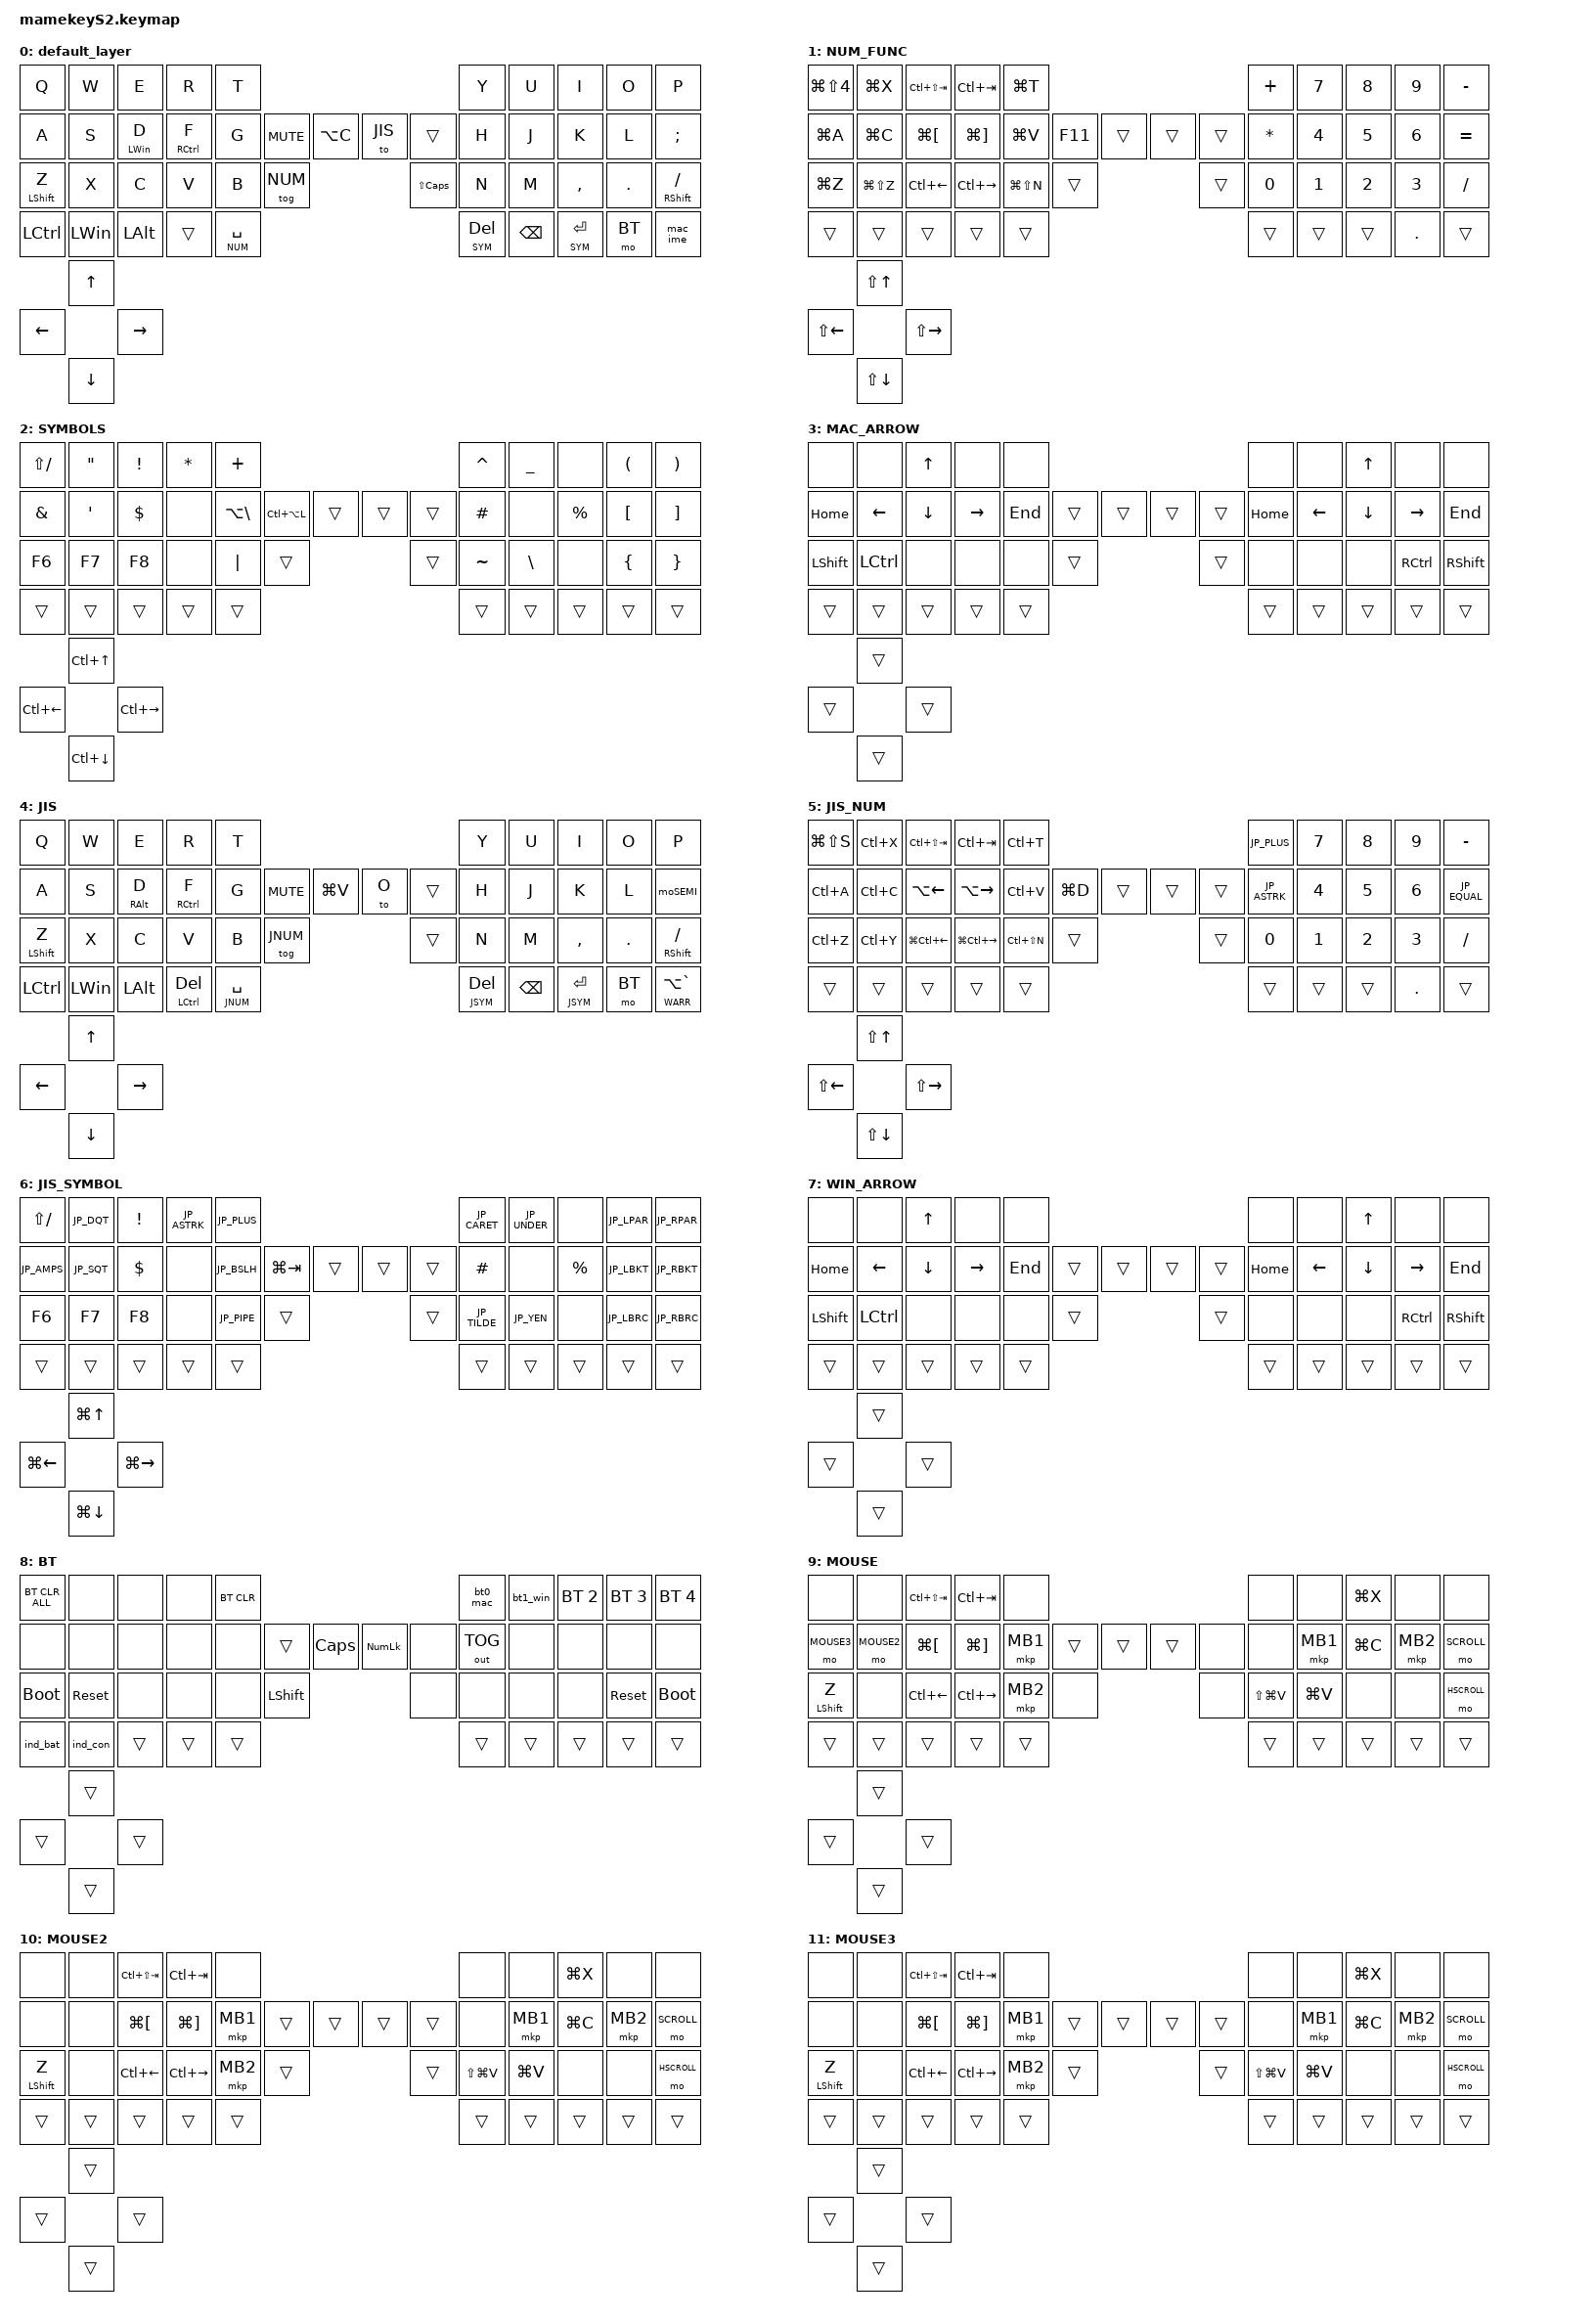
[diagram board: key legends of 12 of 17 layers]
#include <input/processors.dtsi>
#include <behaviors.dtsi>
#include <dt-bindings/zmk/keys.h>
#include <dt-bindings/zmk/bt.h>
#include <dt-bindings/zmk/outputs.h>
#include <dt-bindings/zmk/pointing.h>
#include <dt-bindings/zmk/input_transform.h>
#include <zephyr/dt-bindings/input/input-event-codes.h>


#include <behaviors/rgbled_widget.dtsi>

#define ZMK_POINTING_DEFAULT_SCRL_VAL 100

#define NUM 1 //MAC US
#define SYM 2 //MAC US
#define MARR 3 //MAC
#define JIS 4 //WIN JIS
#define JNUM 5 //WIN JIS
#define JSYM 6 //WIN JIS
#define WARR 7 //WIN
#define BT 8
#define MOUSE 9 //mac
#define MOUSE2 10 //mac lowspeed
#define MOUSE3 11 //mac highspeed
#define WMOUSE 12 //win
#define WMOUSE2 13 //win lowspeed
#define WMOUSE3 14 //win highspeed
#define SCROLL 15
#define HSCROLL 16 //high speed scroll


#define JP_ZKHK  GRAVE        // Zenkaku ↔ Hankaku ↔ Kanji (半角 ↔ 全角 ↔ 漢字)
#define JP_MINUS MINUS        // -
#define JP_CARET EQUAL        // ^
#define JP_YEN   INT3         // ¥
#define JP_AT    LBKT         // @
#define JP_LBKT  RBKT         // [
#define JP_EISU  CAPS         // Eisū (英数)
#define JP_SEMI  SEMI         // ;
#define JP_COLON SQT          // :
#define JP_RBKT  NUHS         // ]
#define JP_COMMA COMMA        // ,
#define JP_DOT   DOT          // .
#define JP_SLASH SLASH        // /
#define JP_BSLH  INT1         // (backslash)
#define JP_MHEN  INT5         // Muhenkan (無変換)
#define JP_HENK  INT4         // Henkan (変換)
#define JP_KANA  INT2         // Katakana ↔ Hiragana ↔ Rōmaji (カタカナ ↔ ひらがな ↔ ローマ字)
#define JP_EXCL  LS(N1)       // !
#define JP_DQT   LS(N2)       // "
#define JP_HASH  LS(N3)       // #
#define JP_DLLR  LS(N4)       // $
#define JP_PRCNT LS(N5)       // %
#define JP_AMPS  LS(N6)       // &
#define JP_SQT   LS(N7)       // '
#define JP_LPAR  LS(N8)       // (
#define JP_RPAR  LS(N9)       // )
#define JP_EQUAL LS(JP_MINUS) // =
#define JP_TILDE LS(JP_CARET) // ~
#define JP_PIPE  LS(JP_YEN)   // |
#define JP_GRAVE LS(JP_AT)    // `
#define JP_LBRC  LS(JP_LBKT)  // {
#define JP_CAPS  LS(JP_EISU)  // Caps Lock
#define JP_PLUS  LS(JP_SEMI)  // +
#define JP_ASTRK LS(JP_COLON) // *
#define JP_RBRC  LS(JP_RBKT)  // }
#define JP_LT    LS(JP_COMMA) // <
#define JP_RT    LS(JP_DOT)   // >
#define JP_QMARK LS(JP_SLASH) // ?
#define JP_UNDER LS(JP_BSLH)  // _

    &mt {
        flavor = "balanced";
        quick-tap-ms = <0>;
    };


//Extend the Auto Mouse Layer (AML) timeout when a mouse key is pressed.
&mkp_input_listener {
         win_aml {
        layers = <4>;
        input-processors = <&zip_temp_layer 12 500>;
    };
         mac_aml {
        layers = <0>;
        input-processors = <&zip_temp_layer 9 500>;
    };
};

/ {

    macros {
        to_layer_0: to_layer_0 {
            compatible = "zmk,behavior-macro-one-param";
            #binding-cells = <1>;
            bindings = <&to 0 &macro_param_1to1 &kp MACRO_PLACEHOLDER>;
            label = "TO_LAYER_0";
        };
        
        exit_AML: exit_AML {
            compatible = "zmk,behavior-macro";
            wait-ms = <0>;
            tap-ms = <0>;
            #binding-cells = <0>;
            bindings = <&tog_off MOUSE>;
            label = "exit_AML";
        };
        
        kp_exit_AML: kp_exit_AML {
            compatible = "zmk,behavior-macro-one-param";
            wait-ms = <0>;
            tap-ms = <0>;
            #binding-cells = <1>;
            bindings = <&macro_param_1to1 &kp MACRO_PLACEHOLDER &exit_AML>;
            label = "KP_exit_AML";
        };

        bt0_mac: bt0_mac {
         compatible = "zmk,behavior-macro";
         #binding-cells = <0>;
         bindings = <&bt BT_SEL 0>, <&to 0>;
};

        bt1_win: bt1_win {
         compatible = "zmk,behavior-macro";
          #binding-cells = <0>;
          bindings = <&bt BT_SEL 1>, <&to JIS>;
};

        mac_ime: mac_ime_toggle {
            compatible = "zmk,behavior-macro";
            #binding-cells = <0>;
            bindings = 
                 <&macro_press>,
                 <&kp LCTRL>,
                 <&macro_tap>,
                 <&kp SPACE>,
                 <&macro_release>,
                 <&kp LCTRL>;
        };

    };
    
    combos {
        compatible = "zmk,combos";

        esc {
            bindings = <&kp ESC>;
            key-positions = <0 1>;
        };        

        shift_tab {
            bindings = <&kp LS(TAB)>;
            key-positions = <1 2>;
        };
        
         tab {
            bindings = <&kp TAB>;
            key-positions = <2 3>;
        };
        
        single_quotation {
            bindings = <&kp SINGLE_QUOTE>;
            layers = <0>; 
            key-positions = <5 6>;
        };
        
        single_quotation_JIS {
            bindings = <&kp JP_SQT>;
            layers = <JIS>; 
            key-positions = <5 6>;
        };
        
        double_quotation {
            bindings = <&kp DOUBLE_QUOTES>;
            layers = <0>; 
            key-positions = <3 4>;
        };
        
        double_quotation_JIS {
            bindings = <&kp JP_DQT>;
            layers = <JIS>; 
            key-positions = <3 4>;
        };
        
        
        minus {
            bindings = <&kp MINUS>;
            key-positions = <8 9>;
        };

        eq {
            bindings = <&kp EQUAL>;
            layers = <0>; 
            key-positions = <34 35>;
        };
        
        eq_JIS {
            bindings = <&kp JP_EQUAL>;
            layers = <JIS>; 
            key-positions = <34 35>;
        };

        mac_layer_L_PARENTHESIS {
            bindings = <&kp LEFT_PARENTHESIS>;
            layers = <0>;
            key-positions = <6 7>;
        };

        mac_layer_R_PARENTHESIS {
            bindings = <&kp RIGHT_PARENTHESIS>;
            layers = <0>;
            key-positions = <7 8>;
        };
        
        win_layer_L_PARENTHESIS {
            bindings = <&kp JP_LPAR>;
            layers = <JIS>;
            key-positions = <6 7>;
        };

        win_layer_R_PARENTHESIS {
            bindings = <&kp JP_RPAR>;
            layers = <JIS>;
            key-positions = <7 8>;
        };
        
        mac_layer_L_BRACKET {
            bindings = <&kp LEFT_BRACKET>;
            layers = <0>;
            key-positions = <20 21>;
        };

        mac_layer_R_BRACKET {
            bindings = <&kp RIGHT_BRACKET>;
            layers = <0>;
            key-positions = <21 22>;
        };
        
        win_layer_L_BRACKET {
            bindings = <&kp JP_LBKT>;
            layers = <JIS>;
            key-positions = <20 21>;
        };

        win_layer_R_BRACKET {
            bindings = <&kp JP_RBKT>;
            layers = <JIS>;
            key-positions = <21 22>;
        };
        
        enter {
            bindings = <&kp ENTER>;
            key-positions = <22 23>;
        };
        
        mac_layer_L_BRACE {
            bindings = <&kp LEFT_BRACE>;
            layers = <0>;
            key-positions = <32 33>;
        };

        mac_layer_R_BRACE {
            bindings = <&kp RIGHT_BRACE>;
            layers = <0>;
            key-positions = <33 34>;
        };
        
        win_layer_L_BRACE {
            bindings = <&kp JP_LBRC>;
            layers = <JIS>;
            key-positions = <32 33>;
        };

        win_layer_R_BRACE {
            bindings = <&kp JP_RBRC>;
            layers = <JIS>;
            key-positions = <33 34>;
        };
        
        mac_layer_arrow {
            bindings = <&mo MARR>;
            layers = <0>; 
            key-positions = <12 13>;
        };

        win_layer_arrow {
            bindings = <&mo WARR>;
            layers = <JIS>; 
            key-positions = <12 13>;
        };        

        ctrl_alt_del {
            bindings = <&kp LC(RA(DEL))>;
            key-positions = <24 25>;
        };

        atmark {
            bindings = <&kp AT_SIGN>; 
            layers = <0>;  
            key-positions = <10 11>;
        };
        atmark_JIS {
            bindings = <&kp JP_AT>; 
            layers = <JIS>;  
            key-positions = <10 11>;
        };
    };

  behaviors {
      
    lt_to_layer_0: lt_to_layer_0 {
            compatible = "zmk,behavior-hold-tap";
            label = "LAYER_TAP_TO_0";
            bindings = <&mo>, <&to_layer_0>;

            #binding-cells = <2>;
            tapping-term-ms = <200>;
        };
        
    tog_off: toggle_layer_off {
            compatible = "zmk,behavior-toggle-layer";
            #binding-cells = <1>;
            display-name = "Toggle Layer Off";
            toggle-mode = "off";
        };

    mt_exit_AML_on_tap: mt_exit_AML_on_tap {
            compatible = "zmk,behavior-hold-tap";
            label = "MT_exit_AML_ON_TAP";
            bindings = <&kp>, <&kp_exit_AML>;

            #binding-cells = <2>;
            tapping-term-ms = <200>;
            flavor = "balanced";
            quick-tap-ms = <200>;
        };    
        
    vol_up_down: behavior_sensor_rotate_volue_up_down {
            compatible = "zmk,behavior-sensor-rotate";
            #sensor-binding-cells = <0>;
            bindings = <&kp C_VOL_DN>, <&kp C_VOL_UP>;
        };         
    
    scroll_up_down: behavior_sensor_rotate_mouse_wheel_up_down {
            compatible = "zmk,behavior-sensor-rotate";
            #sensor-binding-cells = <0>;
            bindings = <&msc SCRL_UP>, <&msc SCRL_DOWN>;
            // 追加: スクロールのタップ時間を設定 (20ms)
            tap-ms = <20>;
        }; 
        
    scroll_left_right: behavior_sensor_rotate_mouse_wheel_left_right {
            compatible = "zmk,behavior-sensor-rotate";
            #sensor-binding-cells = <0>;
            bindings = <&msc SCRL_RIGHT>, <&msc SCRL_LEFT>;
            // 追加: スクロールのタップ時間を設定 (20ms)
            tap-ms = <20>;
        };   
        
    zoom_in_out_win: behavior_sensor_rotate_zoom_in_out_win {
            compatible = "zmk,behavior-sensor-rotate";
            #sensor-binding-cells = <0>;
            bindings = <&kp LC(JP_PLUS)>, <&kp LC(MINUS)>;
            // 追加: スクロールのタップ時間を設定 (20ms)
            tap-ms = <20>;
        };  
    zoom_in_out_mac: behavior_sensor_rotate_zoom_in_out_mac {
            compatible = "zmk,behavior-sensor-rotate";
            #sensor-binding-cells = <0>;
            bindings = <&kp LG(PLUS)>, <&kp LG(MINUS)>;
            // 追加: スクロールのタップ時間を設定 (20ms)
            tap-ms = <20>;
        };     
        
    td_mt: tap_dance_mod_tap {
            compatible = "zmk,behavior-tap-dance";
            #binding-cells = <0>;
            tapping-term-ms = <200>;
            bindings = <&lt WARR LA(GRAVE)>, <&kp LC(SPC)>; 
        };
        
//encorder control WIN  
  //positive
  
    //window change (alt D)   
    w_alt_p: win-alt-gui-positive {
        compatible = "zmk,behavior-mod-morph";
        #binding-cells = <0>;
        bindings = <&none>, <&kp TAB>;
        mods = <(MOD_LALT|MOD_RALT)>;
        keep-mods = <(MOD_RALT)>;
    };
    // tab move (Rctrl F)
    w_r_ctrl_p: win-right-ctrl-positive {
        compatible = "zmk,behavior-mod-morph";
        #binding-cells = <0>;
        bindings = <&none>, <&kp TAB>;
        mods = <(MOD_RCTL)>;
        keep-mods = <(MOD_RCTL)>;
    }; 
    // updown arrow (Lctrl)   
    w_ctrl_p: win-ctrl-positive {
        compatible = "zmk,behavior-mod-morph";
        #binding-cells = <0>;
        bindings = <&w_r_ctrl_p>, <&kp DOWN>;
        mods = <(MOD_LCTL)>;
    };
    // leftright arrow (shift)
    w_shift_p: win-shift-positive {
        compatible = "zmk,behavior-mod-morph";
        #binding-cells = <0>;
        bindings = <&none>, <&kp RIGHT>;
        mods = <(MOD_RSFT|MOD_LSFT)>;
    };     
    w_shift_ctrl_p: win-shift-ctrl-positive {
        compatible = "zmk,behavior-mod-morph";
        #binding-cells = <0>;
        bindings = <&w_shift_p>, <&w_ctrl_p>;
        mods = <(MOD_LCTL|MOD_RCTL)>;
    };
    //none is scroll down
    w_shift_ctrl_none_p: win_shift-ctrl-none-positive {
        compatible = "zmk,behavior-mod-morph";
        #binding-cells = <0>;
        bindings = <&msc SCRL_DOWN>, <&w_shift_ctrl_p>;
        mods = <(MOD_LSFT|MOD_LCTL|MOD_RSFT|MOD_RCTL)>;
    };
    win_enc_p: win-enc-positive {
        compatible = "zmk,behavior-mod-morph";
        #binding-cells = <0>;
        bindings = <&w_shift_ctrl_none_p>, <&w_alt_p>;
        mods = <(MOD_LALT|MOD_RALT)>;
    };
 
 //negative
   
    //window change (alt D)     
    w_alt_n: win-alt-gui-negative {
        compatible = "zmk,behavior-mod-morph";
        #binding-cells = <0>;
        bindings = <&none>, <&kp LS(TAB)>;
        mods = <(MOD_LALT|MOD_RALT)>;
        keep-mods = <(MOD_RALT)>;
    };
    // tab move (Rctrl F)
    w_r_ctrl_n: win-right-ctrl-negative {
        compatible = "zmk,behavior-mod-morph";
        #binding-cells = <0>;
        bindings = <&none>, <&kp LS(TAB)>;
        mods = <(MOD_RCTL)>;
        keep-mods = <(MOD_RCTL)>;
    };
    // updown arrow (Lctrl)    
    w_ctrl_n: win-ctrl-negative {
        compatible = "zmk,behavior-mod-morph";
        #binding-cells = <0>;
        bindings = <&w_r_ctrl_n>, <&kp UP>;
        mods = <(MOD_LCTL)>;
    };
    // leftright arrow (shift)
    w_shift_n: win-shift-negative {
        compatible = "zmk,behavior-mod-morph";
        #binding-cells = <0>;
        bindings = <&none>, <&kp LEFT>;
        mods = <(MOD_RSFT|MOD_LSFT)>;
    };      
    w_shift_ctrl_n: win-shift-ctrl-negative {
        compatible = "zmk,behavior-mod-morph";
        #binding-cells = <0>;
        bindings = <&w_shift_n>, <&w_ctrl_n>;
        mods = <(MOD_LCTL|MOD_RCTL)>;
    };
    //none is scroll up
    w_shift_ctrl_none_n: win_shift-ctrl-none-negative {
        compatible = "zmk,behavior-mod-morph";
        #binding-cells = <0>;
        bindings = <&msc SCRL_UP>, <&w_shift_ctrl_n>;
        mods = <(MOD_LSFT|MOD_LCTL|MOD_RSFT|MOD_RCTL)>;
    };
    win_enc_n: win-enc-negative {
        compatible = "zmk,behavior-mod-morph";
        #binding-cells = <0>;
        bindings = <&w_shift_ctrl_none_n>, <&w_alt_n>;
        mods = <(MOD_LALT|MOD_RALT)>;
    };
    
    win_enc: win-enc {
        compatible = "zmk,behavior-sensor-rotate";
        #sensor-binding-cells = <0>;
        bindings = <&win_enc_n>, <&win_enc_p>;
        tap-ms = <20>;
    };
    
//encorder control MAC
  //positive

    //app select     (command D)    
    m_gui_p: mac-gui-positive {
        compatible = "zmk,behavior-mod-morph";
        #binding-cells = <0>;
        bindings = <&none>, <&kp TAB>;
        mods = <(MOD_LGUI|MOD_RGUI)>;
        keep-mods = <(MOD_LGUI)>;
    };    
    //browser tab move  (Rctrl F)
    m_r_ctrl_p: mac-right-ctrl-positive {
        compatible = "zmk,behavior-mod-morph";
        #binding-cells = <0>;
        bindings = <&none>, <&kp TAB>;
        mods = <(MOD_RCTL)>;
        keep-mods = <(MOD_RCTL)>;

    }; 
    // updown allow (LCtrl) 
    m_ctrl_p: mac-ctrl-positive {
        compatible = "zmk,behavior-mod-morph";
        #binding-cells = <0>;
        bindings = <&m_r_ctrl_p>, <&kp DOWN>;
        mods = <(MOD_LCTL)>;
    }; 
    // LeftRight allow (Shift)
    m_shift_p: mac-shift-positive {
        compatible = "zmk,behavior-mod-morph";
        #binding-cells = <0>;
        bindings = <&none>, <&kp RIGHT>;
        mods = <(MOD_RSFT|MOD_LSFT)>;
    };     
    m_shift_ctrl_p: mac-shift-ctrl-positive {
        compatible = "zmk,behavior-mod-morph";
        #binding-cells = <0>;
        bindings = <&m_shift_p>, <&m_ctrl_p>;
        mods = <(MOD_LCTL|MOD_RCTL)>;
    };
    // none is scroll down
    m_shift_ctrl_none_p: mac_shift-ctrl-none-positive {
        compatible = "zmk,behavior-mod-morph";
        #binding-cells = <0>;
        bindings = <&msc SCRL_DOWN>, <&m_shift_ctrl_p>;
        mods = <(MOD_LSFT|MOD_LCTL|MOD_RSFT|MOD_RCTL)>;
    };
    mac_enc_p: mac-enc-positive {
        compatible = "zmk,behavior-mod-morph";
        #binding-cells = <0>;
        bindings = <&m_shift_ctrl_none_p>, <&m_gui_p>;
        mods = <(MOD_LGUI|MOD_RGUI)>;
    };
    
  //negative    
    
    //app select  (command D)  
    m_gui_n: mac-gui-negative {
        compatible = "zmk,behavior-mod-morph";
        #binding-cells = <0>;
        bindings = <&none>, <&kp LS(TAB)>;
        mods = <(MOD_LGUI|MOD_RGUI)>;
        keep-mods = <(MOD_LGUI)>;
    };    
    //browser tab move (Rctrl F)
    m_r_ctrl_n: mac-right-ctrl-negative {
        compatible = "zmk,behavior-mod-morph";
        #binding-cells = <0>;
        bindings = <&none>, <&kp LS(TAB)>;
        mods = <(MOD_RCTL)>;
        
    }; 
    // Updown allow (LCtrl)   
    m_ctrl_n: mac-ctrl-negative {
        compatible = "zmk,behavior-mod-morph";
        #binding-cells = <0>;
        bindings = <&m_r_ctrl_n>, <&kp UP>;
        mods = <(MOD_LCTL)>;
    }; 
    // LeftRight allow (Shift)
    m_shift_n: mac-shift-negative {
        compatible = "zmk,behavior-mod-morph";
        #binding-cells = <0>;
        bindings = <&none>, <&kp LEFT>;
        mods = <(MOD_RSFT|MOD_LSFT)>; 
    };         
    m_shift_ctrl_n: mac-shift-ctrl-negative {
        compatible = "zmk,behavior-mod-morph";
        #binding-cells = <0>;
        bindings = <&m_shift_n>, <&m_ctrl_n>;
        mods = <(MOD_LCTL|MOD_RCTL)>;
    };
    // none is scroll up
    m_shift_ctrl_none_n: mac_shift-ctrl-none-negative {
        compatible = "zmk,behavior-mod-morph";
        #binding-cells = <0>;
        bindings = <&msc SCRL_UP>, <&m_shift_ctrl_n>;
        mods = <(MOD_LSFT|MOD_LCTL|MOD_RSFT|MOD_RCTL)>;
    };
    mac_enc_n: mac-enc-negative {
        compatible = "zmk,behavior-mod-morph";
        #binding-cells = <0>;
        bindings = <&m_shift_ctrl_none_n>, <&m_gui_n>;
        mods = <(MOD_LGUI|MOD_RGUI)>;
    };
        
    mac_enc: mac-enc {
        compatible = "zmk,behavior-sensor-rotate";
        #sensor-binding-cells = <0>;
        bindings = <&mac_enc_n>, <&mac_enc_p>;
        tap-ms = <20>;
    }; 
     
    
      
    //JIS
    moSEMI: moSEMI {
            compatible = "zmk,behavior-mod-morph";
            #binding-cells = <0>;
            bindings = <&kp JP_SEMI>, <&kp JP_COLON>;
            mods = <(MOD_LSFT|MOD_RSFT)>;
     }; 

 };    



    keymap {
        compatible = "zmk,keymap";

          default_layer {
            bindings = <
&kp Q               &kp W             &kp E             &kp R            &kp T                                                    &kp Y           &kp U          &kp I        &kp O      &kp P
&kp A               &kp S       &mt LEFT_WIN D          &mt RCTRL F      &kp G     &kp C_MUTE   &kp LA(C)   &to JIS  &trans    &kp H           &kp J          &kp K        &kp L      &kp SEMICOLON
&mt_exit_AML_on_tap LEFT_SHIFT Z  &kp X      &kp C      &kp V            &kp B     &tog NUM                          &kp LS(CAPSLOCK)   &kp N      &kp M       &kp COMMA    &kp DOT    &mt RIGHT_SHIFT SLASH
&kp LCTRL           &kp LEFT_WIN      &kp LEFT_ALT      &trans           &lt NUM SPACE   &lt SYM DEL             &kp BACKSPACE   &lt SYM ENTER                       &mo BT           &mac_ime

        &kp UP_ARROW        
&kp LEFT_ARROW  &kp RIGHT_ARROW 
        &kp DOWN_ARROW              
            >;   
            sensor-bindings = <&mac_enc
                               &vol_up_down
            >;
        };

          NUM_FUNC {
            bindings = <
&kp LG(LS(NUMBER_4))  &kp LG(X)   &kp LC(LS(TAB))   &kp LC(TAB)           &kp LG(T)                                         &kp PLUS  &kp NUMBER_7  &kp NUMBER_8  &kp NUMBER_9  &kp MINUS
&kp LG(A)     &kp LG(C)      &kp LG(LEFT_BRACKET)  &kp LG(RIGHT_BRACKET)  &kp LG(V)  &kp F11  &trans  &trans  &trans  &kp ASTERISK  &kp NUMBER_4  &kp NUMBER_5  &kp NUMBER_6  &kp EQUAL
&kp LG(Z)     &kp LG(LS(Z))  &kp LC(LEFT_ARROW)    &kp LC(RIGHT_ARROW)    &kp LG(LS(N))  &trans                  &trans  &kp NUMBER_0  &kp NUMBER_1  &kp NUMBER_2  &kp NUMBER_3  &kp SLASH
&trans        &trans         &trans                &trans                 &trans     &trans                  &trans  &trans                                     &kp PERIOD       &trans

        &kp LS(UP_ARROW)      
&kp LS(LEFT_ARROW)       &kp LS(RIGHT_ARROW)                
      &kp LS(DOWN_ARROW)  
            >; 
            sensor-bindings = <&scroll_up_down
            &zoom_in_out_mac
            >;
        };

          SYMBOLS {
            bindings = <
&kp LS(SLASH)  &kp DOUBLE_QUOTES  &kp EXCLAMATION  &kp ASTERISK  &kp PLUS                                               &kp CARET  &kp UNDERSCORE  &none        &kp LEFT_PARENTHESIS  &kp RIGHT_PARENTHESIS
&kp AMPERSAND  &kp SINGLE_QUOTE   &kp DOLLAR       &none         &kp LA(BACKSLASH)   &kp LC(LA(L))   &trans   &trans   &trans  &kp HASH   &none           &kp PERCENT  &kp LEFT_BRACKET      &kp RIGHT_BRACKET
&kp F6         &kp F7             &kp F8           &none         &kp PIPE            &trans                          &trans  &kp TILDE  &kp BACKSLASH   &none        &kp LEFT_BRACE        &kp RIGHT_BRACE 
&trans         &trans             &trans           &trans        &trans              &trans                          &trans  &trans                                  &trans                &trans 

        &kp LC(UP_ARROW)       
&kp LC(LEFT_ARROW)       &kp LC(RIGHT_ARROW)                
        &kp LC(DOWN_ARROW) 
            >;  
            sensor-bindings = <&scroll_left_right
            &vol_up_down
            >;
        };
        
          MAC_ARROW {
            bindings = <
&none           &none           &kp UP_ARROW    &none            &none                                      &none     &none           &kp UP_ARROW    &none            &none
&kp HOME        &kp LEFT_ARROW  &kp DOWN_ARROW  &kp RIGHT_ARROW  &kp END  &trans  &trans  &trans  &trans    &kp HOME  &kp LEFT_ARROW  &kp DOWN_ARROW  &kp RIGHT_ARROW  &kp END 
&kp LEFT_SHIFT  &kp LCTRL       &none           &none            &none    &trans                  &trans    &none     &none           &none           &kp RCTRL        &kp RIGHT_SHIFT
&trans          &trans          &trans          &trans           &trans   &trans                  &trans    &trans                                    &trans           &trans

        &trans        
&trans         &trans                
        &trans  
            >;
            sensor-bindings = <&scroll_left_right
            &vol_up_down
            >;
        };   
          JIS {
            bindings = <
&kp Q             &kp W             &kp E            &kp R           &kp T                                                    &kp Y          &kp U           &kp I        &kp O      &kp P
&kp A             &kp S        &mt RIGHT_ALT D       &mt RCTRL F     &kp G       &kp C_MUTE  &kp LG(V)  &to O   &trans       &kp H          &kp J           &kp K        &kp L      &moSEMI
&mt_exit_AML_on_tap LEFT_SHIFT Z  &kp X   &kp C      &kp V           &kp B       &tog JNUM                      &trans   &kp N          &kp M           &kp COMMA    &kp DOT    &mt RIGHT_SHIFT SLASH
&kp LCTRL         &kp LEFT_WIN      &kp LEFT_ALT     &mt LCTRL DEL   &lt JNUM SPACE  &lt JSYM DEL         &kp BACKSPACE     &lt JSYM ENTER                      &mo BT     &lt WARR LA(GRAVE)

        &kp UP_ARROW        
&kp LEFT_ARROW  &kp RIGHT_ARROW
        &kp DOWN_ARROW
            >;
            sensor-bindings = <&win_enc
            &vol_up_down
            >;
        };
        
          JIS_NUM {
            bindings = <
&kp LG(LS(S))  &kp LC(X)  &kp LC(LS(TAB))         &kp LC(TAB)              &kp LC(T)                                      &kp JP_PLUS        &kp NUMBER_7  &kp NUMBER_8  &kp NUMBER_9  &kp MINUS
&kp LC(A)      &kp LC(C)  &kp LA(LEFT_ARROW)      &kp LA(RIGHT_ARROW)      &kp LC(V)  &kp LG(D)  &trans  &trans  &trans   &kp JP_ASTRK     &kp NUMBER_4  &kp NUMBER_5  &kp NUMBER_6  &kp JP_EQUAL
&kp LC(Z)      &kp LC(Y)  &kp LG(LC(LEFT_ARROW))  &kp LG(LC(RIGHT_ARROW))  &kp LC(LS(N))  &trans                &trans   &kp NUMBER_0  &kp NUMBER_1  &kp NUMBER_2  &kp NUMBER_3  &kp SLASH
&trans         &trans     &trans                  &trans                   &trans     &trans                  &trans   &trans                                             &kp PERIOD       &trans

        &kp LS(UP_ARROW)      
&kp LS(LEFT_ARROW)       &kp LS(RIGHT_ARROW)                
      &kp LS(DOWN_ARROW) 
            >;
            sensor-bindings = <&scroll_up_down
            &zoom_in_out_win
            >;
        };
        
          JIS_SYMBOL {
            bindings = <
&kp LS(SLASH) &kp JP_DQT  &kp EXCLAMATION  &kp JP_ASTRK  &kp JP_PLUS                                    &kp JP_CARET  &kp JP_UNDER   &none        &kp JP_LPAR  &kp JP_RPAR
&kp JP_AMPS   &kp JP_SQT  &kp DOLLAR       &none         &kp JP_BSLH   &kp LG(TAB)   &trans  &trans  &trans  &kp HASH      &none          &kp PERCENT  &kp JP_LBKT  &kp JP_RBKT
&kp F6        &kp F7      &kp F8           &none         &kp JP_PIPE   &trans                   &trans  &kp JP_TILDE  &kp JP_YEN     &none        &kp JP_LBRC  &kp JP_RBRC 
&trans        &trans      &trans           &trans        &trans        &trans                   &trans  &trans                                    &trans       &trans 

        &kp LG(UP_ARROW)       
&kp LG(LEFT_ARROW)       &kp LG(RIGHT_ARROW)                
        &kp LG(DOWN_ARROW) 
            >;
            sensor-bindings = <&scroll_left_right
            &vol_up_down
            >;
        }; 

          WIN_ARROW {
            bindings = <
&none           &none           &kp UP_ARROW    &none            &none                                    &none     &none           &kp UP_ARROW    &none            &none
&kp HOME        &kp LEFT_ARROW  &kp DOWN_ARROW  &kp RIGHT_ARROW  &kp END  &trans  &trans  &trans  &trans  &kp HOME  &kp LEFT_ARROW  &kp DOWN_ARROW  &kp RIGHT_ARROW  &kp END 
&kp LEFT_SHIFT  &kp LCTRL       &none           &none            &none    &trans                  &trans  &none     &none           &none           &kp RCTRL        &kp RIGHT_SHIFT
&trans          &trans          &trans          &trans           &trans   &trans                  &trans  &trans                              &trans           &trans

        &trans        
&trans         &trans                
        &trans 
            >;
            sensor-bindings = <&scroll_left_right
            &vol_up_down
            >;
        }; 
        
           BT {
            bindings = <
&bt BT_CLR_ALL  &none     &none    &none    &bt BT_CLR                                              &bt0_mac  &bt1_win &bt BT_SEL 2  &bt BT_SEL 3      &bt BT_SEL 4
&none           &none     &none    &none    &none        &trans   &kp CAPSLOCK  &kp KP_NUMLOCK  &none  &out OUT_TOG  &none         &none         &none             &none
&bootloader           &sys_reset     &none    &none    &none        &kp LEFT_SHIFT                               &none  &none         &none         &none         &sys_reset   &bootloader
&ind_bat        &ind_con  &trans   &trans   &trans       &trans                                      &trans  &trans                            &trans            &trans

        &trans        
&trans         &trans                
        &trans 
            >;
            sensor-bindings = <&scroll_left_right
            &vol_up_down
            >;
        }; 
        
         MOUSE {
            bindings = <
&none          &none     &kp LC(LS(TAB))     &kp LC(TAB)     &none                                                              &none         &none         &kp LG(X)         &none      &none
&mo MOUSE3  &mo MOUSE2     &kp LG(LEFT_BRACKET)  &kp LG(RIGHT_BRACKET)    &mkp MB1   &trans            &trans   &trans    &none  &none         &mkp MB1      &kp LG(C)        &mkp MB2      &mo SCROLL
&mt_exit_AML_on_tap LEFT_SHIFT Z    &none   &kp LC(LEFT_ARROW)   &kp LC(RIGHT_ARROW)  &mkp MB2  &none                    &none  &kp LS(LG(V))     &kp LG(V)        &none         &none      &mo HSCROLL
&trans          &trans   &trans   &trans   &trans      &trans                                                &trans  &trans                                           &trans    &trans

        &trans        
&trans         &trans                
        &trans  
            >;
            sensor-bindings = <&scroll_up_down 
            &scroll_left_right                 
             >;
        };                    

         
         MOUSE2 {
            bindings = <
&none          &none     &kp LC(LS(TAB))     &kp LC(TAB)     &none                                             &none         &none         &kp LG(X)         &none      &none
&none           &none     &kp LG(LEFT_BRACKET)  &kp LG(RIGHT_BRACKET)    &mkp MB1   &trans      &trans   &trans  &trans  &none         &mkp MB1      &kp LG(C)         &mkp MB2      &mo SCROLL
&mt_exit_AML_on_tap LEFT_SHIFT Z           &none     &kp LC(LEFT_ARROW)    &kp LC(RIGHT_ARROW)    &mkp MB2        &trans                       &trans  &kp LS(LG(V))        &kp LG(V)        &none         &none      &mo HSCROLL
&trans          &trans   &trans   &trans   &trans       &trans                       &trans  &trans                            &trans            &trans

        &trans        
&trans         &trans                
        &trans  
            >;
            sensor-bindings = <&scroll_up_down 
            &scroll_left_right                 
             >;
        };        

         MOUSE3 {
            bindings = <
&none          &none     &kp LC(LS(TAB))     &kp LC(TAB)     &none                                             &none         &none         &kp LG(X)         &none      &none
&none           &none     &kp LG(LEFT_BRACKET)  &kp LG(RIGHT_BRACKET)    &mkp MB1   &trans      &trans   &trans  &trans  &none         &mkp MB1      &kp LG(C)         &mkp MB2      &mo SCROLL
&mt_exit_AML_on_tap LEFT_SHIFT Z           &none     &kp LC(LEFT_ARROW)    &kp LC(RIGHT_ARROW)    &mkp MB2        &trans                       &trans  &kp LS(LG(V))       &kp LG(V)        &none         &none      &mo HSCROLL
&trans          &trans   &trans   &trans   &trans       &trans                       &trans  &trans                            &trans            &trans

        &trans        
&trans         &trans                
        &trans  
            >;
            sensor-bindings = <&scroll_up_down 
            &scroll_left_right                  
             >;
        }; 
        
     WMOUSE {
            bindings = <
&none          &none     &kp LC(LS(TAB))     &kp LC(TAB)     &none                                             &none         &none         &kp LC(X)         &none      &none
&mo WMOUSE3   &mo WMOUSE2    &kp LA(LEFT_ARROW)      &kp LA(RIGHT_ARROW)    &mkp MB1   &trans      &trans   &trans  &trans  &none         &mkp MB1      &kp LC(C)         &mkp MB2      &mo SCROLL
&mt_exit_AML_on_tap LEFT_SHIFT Z           &none     &kp LG(LC(LEFT_ARROW))  &kp LG(LC(RIGHT_ARROW))    &mkp MB2        &trans                       &trans  &kp LG(V)        &kp LC(V)        &none         &none      &mo HSCROLL
&trans          &trans   &trans   &trans   &trans       &trans                      &trans  &trans                            &trans            &trans

        &trans        
&trans         &trans                
        &trans  
            >;
            sensor-bindings = <&scroll_up_down 
            &scroll_left_right                 
             >;
        };
        
             WMOUSE2 {
            bindings = <
&none          &none     &kp LC(LS(TAB))     &kp LC(TAB)     &none                                             &none         &none         &kp LC(X)         &none      &none
&mo WMOUSE3   &mo WMOUSE2    &kp LA(LEFT_ARROW)      &kp LA(RIGHT_ARROW)    &mkp MB1   &trans      &trans   &trans  &trans  &none         &mkp MB1      &kp LC(C)         &mkp MB2      &mo SCROLL
&mt_exit_AML_on_tap LEFT_SHIFT Z           &none     &kp LG(LC(LEFT_ARROW))  &kp LG(LC(RIGHT_ARROW))    &mkp MB2       &trans                       &trans  &kp LG(V)         &kp LC(V)        &none         &none      &mo HSCROLL
&trans          &trans   &trans   &trans   &trans       &trans                      &trans  &trans                            &trans            &trans

        &trans        
&trans         &trans                
        &trans  
            >;
            sensor-bindings = <&scroll_up_down 
            &scroll_left_right                  
             >;
        };
        
             WMOUSE3 {
            bindings = <
&none          &none     &kp LC(LS(TAB))     &kp LC(TAB)     &none                                             &none         &none         &kp LC(X)         &none      &none
&mo WMOUSE3   &mo WMOUSE2    &kp LA(LEFT_ARROW)      &kp LA(RIGHT_ARROW)    &mkp MB1  &trans      &trans   &trans  &trans  &none         &mkp MB1      &kp LC(C)         &mkp MB2      &mo SCROLL
&mt_exit_AML_on_tap LEFT_SHIFT Z           &none     &kp LG(LC(LEFT_ARROW))  &kp LG(LC(RIGHT_ARROW))    &mkp MB2        &trans                       &trans  &kp LG(V)        &kp LC(V)        &none         &none      &mo HSCROLL
&trans          &trans   &trans   &trans   &trans       &trans                      &trans  &trans                            &trans            &trans

        &trans        
&trans         &trans                
        &trans  
            >;
            sensor-bindings = <&scroll_up_down 
            &scroll_left_right             
             >;
        }; 
        
          SCROLL {
            bindings = <
&none          &none     &none    &none     &none                                             &none         &none         &none         &none      &none
&none           &none     &none    &none    &none        &trans      &trans   &trans  &trans  &none         &none         &none         &none      &none
&none           &none     &none    &none    &none        &trans                       &trans  &none         &none         &none         &none      &none
&trans          &trans   &trans   &trans   &trans       &trans                       &trans  &trans                            &trans            &trans

        &trans        
&trans         &trans                
        &trans 
            >;
            sensor-bindings = <&scroll_left_right
                               &scroll_up_down
            >;
        };   
        
            HSCROLL {
            bindings = <
&none          &none     &none    &none     &none                                             &none         &none         &none         &none      &none
&none           &none     &none    &none    &none        &trans      &trans   &trans  &trans  &none         &none         &none         &none      &none
&none           &none     &none    &none    &none        &trans                       &trans  &none         &none         &none         &none      &none
&trans          &trans   &trans   &trans   &trans       &trans                       &trans  &trans                            &trans            &trans

        &trans        
&trans         &trans                
        &trans 
            >;
            sensor-bindings = <&scroll_left_right
                               &scroll_up_down
            >;
        }; 
      };                 
};
